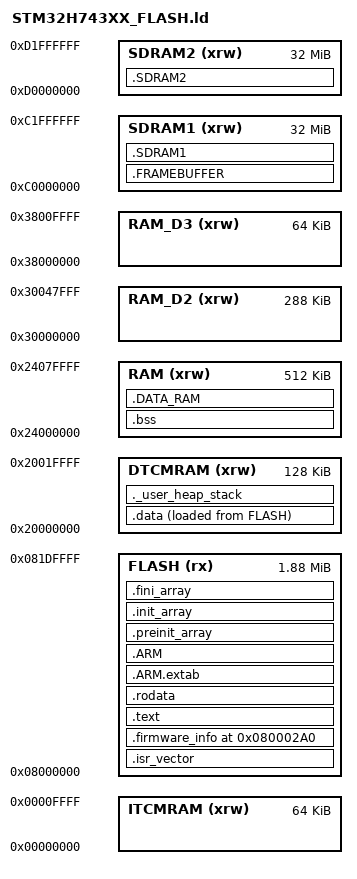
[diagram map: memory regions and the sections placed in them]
/*
 * SPDX-License-Identifier: BSD-3-Clause
 *
 * Copyright (c) 2025 STMicroelectronics.
 * Copyright (c) 2025 xiphonics, inc.
 *
 * This file is part of the picoTracker firmware
 */

/* Entry Point */
ENTRY(Reset_Handler)

/* Highest address of the user mode stack */
_estack = ORIGIN(DTCMRAM) + LENGTH(DTCMRAM);    /* end of RAM */
/* Generate a link error if heap and stack don't fit into RAM */
_Min_Heap_Size = 0x200;      /* required amount of heap  */
_Min_Stack_Size = 0x400; /* required amount of stack */

/* Specify the memory areas */
MEMORY
{
DTCMRAM (xrw)      : ORIGIN = 0x20000000, LENGTH = 128K
RAM (xrw)      : ORIGIN = 0x24000000, LENGTH = 512K
RAM_D2 (xrw)      : ORIGIN = 0x30000000, LENGTH = 288K
RAM_D3 (xrw)      : ORIGIN = 0x38000000, LENGTH = 64K
ITCMRAM (xrw)      : ORIGIN = 0x00000000, LENGTH = 64K
/* FLASH size: 15 sectors of spanning BANK1 and BANK2, 16th sector is bootloader */
FLASH (rx)      : ORIGIN = 0x8000000, LENGTH = 1920K
SDRAM1 (xrw) : ORIGIN = 0xC0000000, LENGTH = 32M
SDRAM2 (xrw) : ORIGIN = 0xD0000000, LENGTH = 32M
}

/* Define output sections */
SECTIONS
{
  /* The startup code goes first into FLASH */
  .isr_vector :
  {
    . = ALIGN(4);
    KEEP(*(.isr_vector)) /* Startup code */
    . = ALIGN(4);
  } >FLASH

  /* Firmware information for release image intended to be loaded from bootloader
  firmware_info field is 16 bytes, record at the end of sector */
  .firmware_info 0x080002A0 : ALIGN(4)
  {
    KEEP(*(.firmware_info))
  } > FLASH

  /* The program code and other data goes into FLASH */
  .text :
  {
    . = ALIGN(4);
    *(.text)           /* .text sections (code) */
    *(.text*)          /* .text* sections (code) */
    *(.glue_7)         /* glue arm to thumb code */
    *(.glue_7t)        /* glue thumb to arm code */
    *(.eh_frame)

    KEEP (*(.init))
    KEEP (*(.fini))

    . = ALIGN(4);
    _etext = .;        /* define a global symbols at end of code */
  } >FLASH

  /* Constant data goes into FLASH */
  .rodata :
  {
    . = ALIGN(4);
    *(.rodata)         /* .rodata sections (constants, strings, etc.) */
    *(.rodata*)        /* .rodata* sections (constants, strings, etc.) */
    . = ALIGN(4);
  } >FLASH

  .ARM.extab (READONLY) : /* The "READONLY" keyword is only supported in GCC11 and later, remove it if using GCC10 or earlier. */
  {
    . = ALIGN(4);
    *(.ARM.extab* .gnu.linkonce.armextab.*)
    . = ALIGN(4);
  } >FLASH

  .ARM (READONLY) : /* The "READONLY" keyword is only supported in GCC11 and later, remove it if using GCC10 or earlier. */
  {
    . = ALIGN(4);
    __exidx_start = .;
    *(.ARM.exidx*)
    __exidx_end = .;
    . = ALIGN(4);
  } >FLASH

  .preinit_array (READONLY) : /* The "READONLY" keyword is only supported in GCC11 and later, remove it if using GCC10 or earlier. */
  {
    . = ALIGN(4);
    PROVIDE_HIDDEN (__preinit_array_start = .);
    KEEP (*(.preinit_array*))
    PROVIDE_HIDDEN (__preinit_array_end = .);
    . = ALIGN(4);
  } >FLASH

  .init_array (READONLY) : /* The "READONLY" keyword is only supported in GCC11 and later, remove it if using GCC10 or earlier. */
  {
    . = ALIGN(4);
    PROVIDE_HIDDEN (__init_array_start = .);
    KEEP (*(SORT(.init_array.*)))
    KEEP (*(.init_array*))
    PROVIDE_HIDDEN (__init_array_end = .);
    . = ALIGN(4);
  } >FLASH

  .fini_array (READONLY) : /* The "READONLY" keyword is only supported in GCC11 and later, remove it if using GCC10 or earlier. */
  {
    . = ALIGN(4);
    PROVIDE_HIDDEN (__fini_array_start = .);
    KEEP (*(SORT(.fini_array.*)))
    KEEP (*(.fini_array*))
    PROVIDE_HIDDEN (__fini_array_end = .);
    . = ALIGN(4);
  } >FLASH

  /* used by the startup to initialize data */
  _sidata = LOADADDR(.data);

  /* Initialized data sections goes into RAM, load LMA copy after code */
  .data :
  {
    . = ALIGN(4);
    _sdata = .;        /* create a global symbol at data start */
    *(.data)           /* .data sections */
    *(.data*)          /* .data* sections */
    *(.RamFunc)        /* .RamFunc sections */
    *(.RamFunc*)       /* .RamFunc* sections */

    . = ALIGN(4);
    _edata = .;        /* define a global symbol at data end */
  } >DTCMRAM AT> FLASH


  /* Uninitialized data section */
  . = ALIGN(4);
  .bss :
  {
    /* This is used by the startup in order to initialize the .bss secion */
    _sbss = .;         /* define a global symbol at bss start */
    __bss_start__ = _sbss;
    *(.bss)
    *(.bss*)
    *(COMMON)

    . = ALIGN(4);
    _ebss = .;         /* define a global symbol at bss end */
    __bss_end__ = _ebss;
/*  } >DTCMRAM */
  /* TODO(stm): need to do this much more granular, right now we move everything to RAM to make sure it fits */
  } > RAM

  /* User_heap_stack section, used to check that there is enough RAM left */
  ._user_heap_stack :
  {
    . = ALIGN(8);
    PROVIDE ( end = . );
    PROVIDE ( _end = . );
    . = . + _Min_Heap_Size;
    . = . + _Min_Stack_Size;
    . = ALIGN(8);
  } >DTCMRAM


  .DATA_RAM (NOLOAD):
  {
    *(.DATA_RAM)
  } >RAM

  .FRAMEBUFFER (NOLOAD):
  {
  . = ALIGN(32);  /* Align for better performance */
  *(.FRAMEBUFFER)
  . = ALIGN(32);
  } >SDRAM1

.SDRAM1 (NOLOAD) : {
. = ALIGN(32);
*(.SDRAM1 .SDRAM1.*)
. = ALIGN(32);
} > SDRAM1

.SDRAM2 (NOLOAD) : {
. = ALIGN(32);
*(.SDRAM2 .SDRAM2.*)
. = ALIGN(32);
} > SDRAM2


  /* Remove information from the standard libraries */
  /DISCARD/ :
  {
    libc.a ( * )
    libm.a ( * )
    libgcc.a ( * )
  }

}


